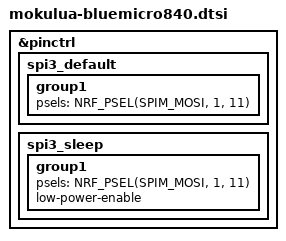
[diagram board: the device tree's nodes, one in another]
/*
 * Copyright (c) 2023 The ZMK Contributors
 *
 * SPDX-License-Identifier: MIT
 */

#include "mokulua-nrf52.dtsi"

&pinctrl {
    spi3_default: spi3_default {
        group1 {
            psels = <NRF_PSEL(SPIM_MOSI, 1, 11)>;
        };
    };

    spi3_sleep: spi3_sleep {
        group1 {
            psels = <NRF_PSEL(SPIM_MOSI, 1, 11)>;
            low-power-enable;
        };
    };
};
